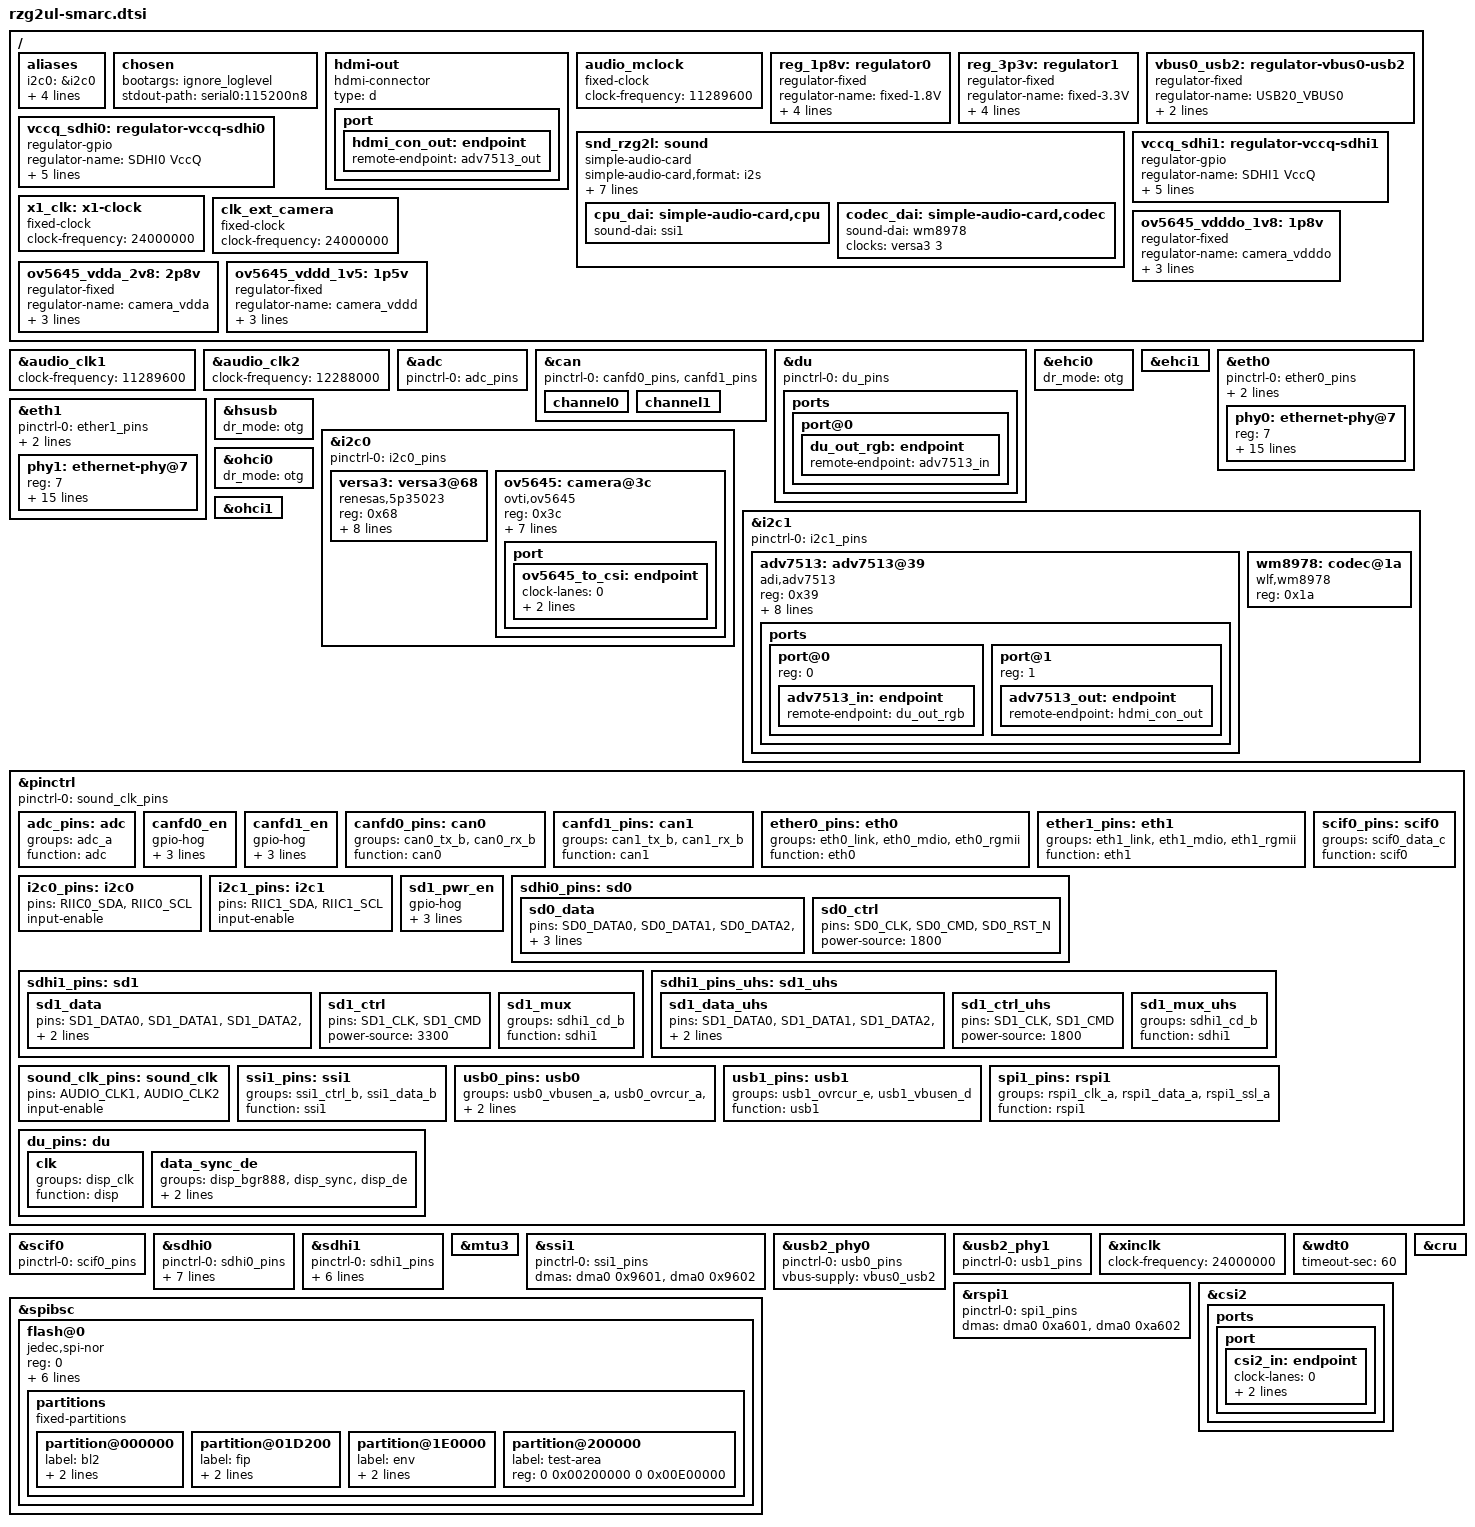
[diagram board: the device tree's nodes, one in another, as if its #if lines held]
// SPDX-License-Identifier: GPL-2.0
/*
 * Device Tree Source for the RZG2UL Evaluation Board Kit
 *
 * Copyright (C) 2021 Renesas Electronics Corp.
 */

#include <dt-bindings/pinctrl/pinctrl-rzg2l.h>
#include <dt-bindings/gpio/gpio.h>

/*
 * DIP-Switch SW1 setting
 * 1 : High; 0: Low
 * SW1-2 : SW_SD0_DEV_SEL	(1: eMMC; 0: uSD)
 * SW1-3 : SW_ET0_EN_N		(0: ETHER0; 1: CAN0,CAN1,SSI1,RSPI1)
 * Please change below MACROs corespondingly to SW1 setting
 */

#define	SW_SW0_DEV_SEL	1
#define	SW_ET0_EN_N	1

/ {
	aliases {
		i2c0 = &i2c0;
		i2c1 = &i2c1;
		serial0 = &scif0;
#if !(SW_ET0_EN_N)
		ethernet0 = &eth0;
#endif
		ethernet1 = &eth1;
	};

	chosen {
		bootargs = "ignore_loglevel";
		stdout-path = "serial0:115200n8";
	};

	hdmi-out {
		compatible = "hdmi-connector";
		type = "d";

		port {
			hdmi_con_out: endpoint {
				remote-endpoint = <&adv7513_out>;
			};
		};
	};

	audio_mclock: audio_mclock {
		compatible = "fixed-clock";
		#clock-cells = <0>;
		clock-frequency = <11289600>;
	};

	reg_1p8v: regulator0 {
		compatible = "regulator-fixed";

		regulator-name = "fixed-1.8V";
		regulator-min-microvolt = <1800000>;
		regulator-max-microvolt = <1800000>;
		regulator-boot-on;
		regulator-always-on;
	};

	reg_3p3v: regulator1 {
		compatible = "regulator-fixed";

		regulator-name = "fixed-3.3V";
		regulator-min-microvolt = <3300000>;
		regulator-max-microvolt = <3300000>;
		regulator-boot-on;
		regulator-always-on;
	};

	vbus0_usb2: regulator-vbus0-usb2 {
		compatible = "regulator-fixed";

		regulator-name = "USB20_VBUS0";
		regulator-min-microvolt = <5000000>;
		regulator-max-microvolt = <5000000>;
	};

#if (SW_ET0_EN_N)
	snd_rzg2l: sound {
		compatible = "simple-audio-card";
		simple-audio-card,format = "i2s";
		simple-audio-card,bitclock-master = <&cpu_dai>;
		simple-audio-card,frame-master = <&cpu_dai>;
		simple-audio-card,mclk-fs = <256>;

		simple-audio-card,widgets = "Microphone", "Microphone Jack";
		simple-audio-card,routing =
			    "L2", "Mic Bias",
			    "R2", "Mic Bias",
			    "Mic Bias", "Microphone Jack";

		cpu_dai: simple-audio-card,cpu {
			sound-dai = <&ssi1>;
		};

		codec_dai: simple-audio-card,codec {
			sound-dai = <&wm8978>;
			clocks = <&versa3 3>;
		};
	};
#endif

#if !(SW_SW0_DEV_SEL)
	vccq_sdhi0: regulator-vccq-sdhi0 {
		compatible = "regulator-gpio";

		regulator-name = "SDHI0 VccQ";
		regulator-min-microvolt = <1800000>;
		regulator-max-microvolt = <3300000>;

		gpios = <&pinctrl RZG2L_GPIO(6, 2) GPIO_ACTIVE_HIGH>;

		gpios-states = <1>;
		states = <3300000 1
			  1800000 0>;
	};
#endif

	vccq_sdhi1: regulator-vccq-sdhi1 {
		compatible = "regulator-gpio";

		regulator-name = "SDHI1 VccQ";
		regulator-min-microvolt = <1800000>;
		regulator-max-microvolt = <3300000>;

		gpios = <&pinctrl RZG2L_GPIO(6, 1) GPIO_ACTIVE_HIGH>;

		gpios-states = <1>;
		states = <3300000 1
			  1800000 0>;
	};

	x1_clk: x1-clock {
		compatible = "fixed-clock";
		#clock-cells = <0>;
		clock-frequency = <24000000>;
	};

	clk_ext_camera: clk_ext_camera {
		compatible = "fixed-clock";
		#clock-cells = <0>;
		clock-frequency = <24000000>;
	};

	ov5645_vdddo_1v8: 1p8v {
		compatible = "regulator-fixed";
		regulator-name = "camera_vdddo";
		regulator-min-microvolt = <1800000>;
		regulator-max-microvolt = <1800000>;
		regulator-always-on;
	};

	ov5645_vdda_2v8: 2p8v {
		compatible = "regulator-fixed";
		regulator-name = "camera_vdda";
		regulator-min-microvolt = <2800000>;
		regulator-max-microvolt = <2800000>;
		regulator-always-on;
	};

	ov5645_vddd_1v5: 1p5v {
		compatible = "regulator-fixed";
		regulator-name = "camera_vddd";
		regulator-min-microvolt = <1500000>;
		regulator-max-microvolt = <1500000>;
		regulator-always-on;
	};
};

&audio_clk1{
	clock-frequency = <11289600>;
};

&audio_clk2{
	clock-frequency = <12288000>;
};

#if (SW_SW0_DEV_SEL)
&adc {
	pinctrl-0 = <&adc_pins>;
	pinctrl-names = "default";
	status = "okay";
};
#endif

#if (SW_ET0_EN_N)
&can {
	pinctrl-0 = <&canfd0_pins &canfd1_pins>;
	pinctrl-names = "default";
	status = "okay";
	channel0 {
		status = "okay";
	};
	channel1 {
		status = "okay";
	};
};
#endif

&du {
	pinctrl-0 = <&du_pins>;
	pinctrl-names = "default";
	status = "okay";

	ports {
		port@0 {
			du_out_rgb: endpoint {
				remote-endpoint = <&adv7513_in>;
			};
		};
	};
};

&ehci0 {
	dr_mode = "otg";
	status = "okay";
};

&ehci1 {
	status = "okay";
};

#if !(SW_ET0_EN_N)
&eth0 {
	pinctrl-0 = <&ether0_pins>;
	pinctrl-names = "default";
	phy-handle = <&phy0>;
	phy-mode = "rgmii";
	status = "okay";

	phy0: ethernet-phy@7 {
		reg = <7>;
		rxc-skew-psec = <2400>;
		txc-skew-psec = <2400>;
		rxdv-skew-psec = <0>;
		txdv-skew-psec = <0>;
		rxd0-skew-psec = <0>;
		rxd1-skew-psec = <0>;
		rxd2-skew-psec = <0>;
		rxd3-skew-psec = <0>;
		txd0-skew-psec = <0>;
		txd1-skew-psec = <0>;
		txd2-skew-psec = <0>;
		txd3-skew-psec = <0>;

		interrupt-parent = <&pinctrl>;
		interrupts = <RZG2L_GPIO(5, 1) IRQ_TYPE_EDGE_FALLING>;
	};
};
#endif

&eth1 {
	pinctrl-0 = <&ether1_pins>;
	pinctrl-names = "default";
	phy-handle = <&phy1>;
	phy-mode = "rgmii";
	status = "okay";

	phy1: ethernet-phy@7 {
		reg = <7>;
		rxc-skew-psec = <2400>;
		txc-skew-psec = <2400>;
		rxdv-skew-psec = <0>;
		txdv-skew-psec = <0>;
		rxd0-skew-psec = <0>;
		rxd1-skew-psec = <0>;
		rxd2-skew-psec = <0>;
		rxd3-skew-psec = <0>;
		txd0-skew-psec = <0>;
		txd1-skew-psec = <0>;
		txd2-skew-psec = <0>;
		txd3-skew-psec = <0>;

		interrupt-parent = <&pinctrl>;
		interrupts = <RZG2L_GPIO(18, 5) IRQ_TYPE_EDGE_FALLING>;
	};
};

&hsusb {
	dr_mode = "otg";
	status = "okay";
};

&i2c0 {
	pinctrl-0 = <&i2c0_pins>;
	pinctrl-names = "default";

	status = "okay";

	versa3: versa3@68 {
		compatible = "renesas,5p35023";
		reg = <0x68>;
		#clock-cells = <1>;
		clocks = <&x1_clk>;
		clock-names = "x1";
		assigned-clocks = <&versa3 0>,
				   <&versa3 1>,
				   <&versa3 2>,
				   <&versa3 3>,
				   <&versa3 4>,
				   <&versa3 5>;
		assigned-clock-rates =	<12288000>, <25000000>,
					<12000000>, <11289600>,
					<11289600>, <24000000>;
		clock-divider-read-only = <1>, <1>, <1>, <1>, <1>;
		clock-flags = <2176>, <2176>, <2176>, <2052>, <2176>, <2048>;
	};

	ov5645: camera@3c {
		compatible = "ovti,ov5645";
		reg = <0x3c>;
		clock-names = "xclk";
		clocks = <&clk_ext_camera>;
		clock-frequency = <24000000>;
		vdddo-supply = <&ov5645_vdddo_1v8>;
		vdda-supply = <&ov5645_vdda_2v8>;
		vddd-supply = <&ov5645_vddd_1v5>;
#if (SW_ET0_EN_N)
		enable-gpios = <&pinctrl RZG2L_GPIO(4, 4) GPIO_ACTIVE_HIGH>;
#else
		/* dummy */
		enable-gpios = <&pinctrl RZG2L_GPIO(8, 1) GPIO_ACTIVE_HIGH>;
#endif
		reset-gpios = <&pinctrl RZG2L_GPIO(0, 1) GPIO_ACTIVE_LOW>;

		port {
			ov5645_to_csi: endpoint {
				clock-lanes = <0>;
				data-lanes = <1 2>;
				remote-endpoint = <&csi2_in>;
			};
		};
	};
};

&i2c1 {
	pinctrl-0 = <&i2c1_pins>;
	pinctrl-names = "default";

	status = "okay";

	adv7513: adv7513@39 {
		compatible = "adi,adv7513";
		reg = <0x39>;

		adi,input-depth = <8>;
		adi,input-colorspace = "rgb";
		adi,input-clock = "1x";

		avdd-supply = <&reg_1p8v>;
		dvdd-supply = <&reg_1p8v>;
		pvdd-supply = <&reg_1p8v>;
		dvdd-3v-supply = <&reg_3p3v>;
		bgvdd-supply = <&reg_1p8v>;

		ports {
			#address-cells = <1>;
			#size-cells = <0>;

			port@0 {
				reg = <0>;

				adv7513_in: endpoint {
					remote-endpoint = <&du_out_rgb>;
				};
			};

			port@1 {
				reg = <1>;

				adv7513_out: endpoint {
					remote-endpoint = <&hdmi_con_out>;
				};
			};
		};
	};

#if (SW_ET0_EN_N)
	wm8978: codec@1a {
		compatible = "wlf,wm8978";
		#sound-dai-cells = <0>;
		reg = <0x1a>;
	};
#endif
};

&ohci0 {
	dr_mode = "otg";
	status = "okay";
};

&ohci1 {
	status = "okay";
};

&pinctrl {
	pinctrl-0 = <&sound_clk_pins>;
	pinctrl-names = "default";

#if (SW_SW0_DEV_SEL)
	adc_pins: adc {
		groups = "adc_a";
		function = "adc";
	};
#endif

#if (SW_ET0_EN_N)
	canfd0_en {
		gpio-hog;
		gpios = <RZG2L_GPIO(2, 2) GPIO_ACTIVE_LOW>;
		output-high;
		line-name = "canfd0_en";
	};

	canfd1_en {
		gpio-hog;
		gpios = <RZG2L_GPIO(2, 3) GPIO_ACTIVE_LOW>;
		output-high;
		line-name = "canfd1_en";
	};

	canfd0_pins: can0 {
		groups = "can0_tx_b", "can0_rx_b";
		function = "can0";
	};

	canfd1_pins: can1 {
		groups = "can1_tx_b", "can1_rx_b";
		function = "can1";
	};
#endif

#if !(SW_ET0_EN_N)
	ether0_pins: eth0 {
		groups = "eth0_link", "eth0_mdio", "eth0_rgmii";
		function = "eth0";
	};
#endif
	ether1_pins: eth1 {
		groups = "eth1_link", "eth1_mdio", "eth1_rgmii";
		function = "eth1";
	};

	i2c0_pins: i2c0 {
		pins = "RIIC0_SDA", "RIIC0_SCL";
		input-enable;
	};

	i2c1_pins: i2c1 {
		pins = "RIIC1_SDA", "RIIC1_SCL";
		input-enable;
	};

	scif0_pins: scif0 {
		groups = "scif0_data_c";
		function = "scif0";
	};

	sd1_pwr_en {
		gpio-hog;
		gpios = <RZG2L_GPIO(0, 3) GPIO_ACTIVE_HIGH>;
		output-high;
		line-name = "sd1_pwr_en";
	};

#if (SW_SW0_DEV_SEL)
	/* Support pinctrl for MMC function of SDHI0*/
	sdhi0_pins: sd0 {
		sd0_data {
			pins =  "SD0_DATA0", "SD0_DATA1", "SD0_DATA2",
				"SD0_DATA3", "SD0_DATA4", "SD0_DATA5",
				"SD0_DATA6", "SD0_DATA7";
			power-source  = <1800>;
		};

		sd0_ctrl {
			pins = "SD0_CLK", "SD0_CMD", "SD0_RST_N";
			power-source = <1800>;
		};
	};
#else
	/* Support pinctrl for SD function of SDHI0 */
	sdhi0_pins: sd0 {
		sd0_data {
			pins =  "SD0_DATA0", "SD0_DATA1", "SD0_DATA2",
				"SD0_DATA3";
			power-source  = <3300>;
		};

		sd0_ctrl {
			pins = "SD0_CLK", "SD0_CMD";
			power-source = <3300>;
		};

		sd0_mux {
			groups = "sdhi0_cd_a";
			function = "sdhi0";
		};
	};

	sdhi0_pins_uhs: sd0_uhs {
		sd0_data_uhs {
			pins =	"SD0_DATA0", "SD0_DATA1", "SD0_DATA2",
				"SD0_DATA3";
			power-source  = <1800>;
		};

		sd0_ctrl_uhs {
			pins = "SD0_CLK", "SD0_CMD";
			power-source  = <1800>;
		};

		sd0_mux_uhs {
			groups = "sdhi0_cd_a";
			function = "sdhi0";
		};
	};
#endif

	sdhi1_pins: sd1 {
		sd1_data {
			pins =	"SD1_DATA0", "SD1_DATA1",
				"SD1_DATA2", "SD1_DATA3";
			power-source  = <3300>;
		};

		sd1_ctrl {
			pins = "SD1_CLK", "SD1_CMD";
			power-source  = <3300>;
		};

		sd1_mux {
			groups = "sdhi1_cd_b";
			function = "sdhi1";
		};
	};

	sdhi1_pins_uhs: sd1_uhs {
		sd1_data_uhs {
			pins =	"SD1_DATA0", "SD1_DATA1",
				"SD1_DATA2", "SD1_DATA3";
			power-source  = <1800>;
		};

		sd1_ctrl_uhs {
			pins = "SD1_CLK", "SD1_CMD";
			power-source  = <1800>;
		};

		sd1_mux_uhs {
			groups = "sdhi1_cd_b";
			function = "sdhi1";
		};
	};

	sound_clk_pins: sound_clk {
		pins = "AUDIO_CLK1", "AUDIO_CLK2";
		input-enable;
	};

#if (SW_ET0_EN_N)
	ssi1_pins: ssi1 {
		groups = "ssi1_ctrl_b", "ssi1_data_b";
		function = "ssi1";
	};
#endif

	usb0_pins: usb0 {
		groups = "usb0_vbusen_a", "usb0_ovrcur_a", "usb0_otg_id_a";
		function = "usb0";
	};

	usb1_pins: usb1 {
		groups = "usb1_ovrcur_e", "usb1_vbusen_d";
		function = "usb1";
	};

#if (SW_ET0_EN_N)
	spi1_pins: rspi1 {
		groups = "rspi1_clk_a", "rspi1_data_a", "rspi1_ssl_a";
		function = "rspi1";
	};
#endif

	du_pins: du {
		clk {
			groups = "disp_clk";
			function = "disp";
		};

		data_sync_de {
			groups = "disp_bgr888", "disp_sync", "disp_de";
			function = "disp";
			drive-strength = <2>;
		};
	};
};

&scif0 {
	pinctrl-0 = <&scif0_pins>;
	pinctrl-names = "default";
	status = "okay";
};

#if (SW_SW0_DEV_SEL)
&sdhi0 {
	pinctrl-0 = <&sdhi0_pins>;
	pinctrl-1 = <&sdhi0_pins>;
	pinctrl-names = "default", "state_uhs";

	vmmc-supply = <&reg_3p3v>;
	vqmmc-supply = <&reg_1p8v>;
	bus-width = <8>;
	mmc-hs200-1_8v;
	non-removable;
	fixed-emmc-driver-type = <1>;
	status = "okay";
};
#else
&sdhi0 {
	pinctrl-0 = <&sdhi0_pins>;
	pinctrl-1 = <&sdhi0_pins_uhs>;
	pinctrl-names = "default", "state_uhs";

	vmmc-supply = <&reg_3p3v>;
	vqmmc-supply = <&vccq_sdhi0>;

	bus-width = <4>;
	sd-uhs-sdr50;
	sd-uhs-sdr104;
	status = "okay";
};
#endif

&sdhi1 {
	pinctrl-0 = <&sdhi1_pins>;
	pinctrl-1 = <&sdhi1_pins_uhs>;
	pinctrl-names = "default", "state_uhs";

	vmmc-supply = <&reg_3p3v>;
	vqmmc-supply = <&vccq_sdhi1>;

	bus-width = <4>;
	sd-uhs-sdr50;
	sd-uhs-sdr104;
	status = "okay";
};

&mtu3 {
	status = "okay";
};

#if (SW_ET0_EN_N)
&ssi1 {
	pinctrl-0 = <&ssi1_pins>;
	pinctrl-names = "default";

	dmas = <&dma0 0x9601>,
	       <&dma0 0x9602>;
	dma-names = "tx", "rx";

	status = "okay";
};
#endif

&usb2_phy0 {
	pinctrl-0 = <&usb0_pins>;
	pinctrl-names = "default";

	vbus-supply = <&vbus0_usb2>;
	status = "okay";
};

&usb2_phy1 {
	pinctrl-0 = <&usb1_pins>;
	pinctrl-names = "default";

	status = "okay";
};

&xinclk {
	clock-frequency = <24000000>;
};

&wdt0 {
	status = "okay";
	timeout-sec = <60>;
};

#if (SW_ET0_EN_N)
&rspi1 {
	pinctrl-0 = <&spi1_pins>;
	pinctrl-names = "default";
	status = "okay";
	dmas = <&dma0 0xa601>,
	       <&dma0 0xa602>;
	dma-names = "tx", "rx";
};
#endif

&spibsc {
	status = "okay";

	flash@0 {
		compatible = "jedec,spi-nor";
		reg = <0>;
		spi-max-frequency = <30000000>;

		spi-tx-bus-width = <1>;
		spi-rx-bus-width = <1>;

		/* SPI Mode 3 */
		spi-cpol;
		spi-cpha;
		m25p,fast-read;

		partitions {
			compatible = "fixed-partitions";
			#address-cells = <2>;
			#size-cells = <2>;

			partition@000000 {
				label = "bl2";
				reg = <0 0x00000000 0 0x0001D200>;
				read-only;
			};
			partition@01D200 {
				label = "fip";
				reg = <0 0x0001D200 0 0x001C2E00>;
				read-only;
			};
			partition@1E0000 {
				label = "env";
				reg = <0 0x001E0000 0 0x00020000>;
				read-only;
			};
			partition@200000 {
				label = "test-area";
				reg = <0 0x00200000 0 0x00E00000>;
			};
		};
	};
};

&cru {
	status = "okay";
};

&csi2 {
	status = "okay";

	ports {
		port {
			csi2_in: endpoint {
				clock-lanes = <0>;
				data-lanes = <1 2>;
				remote-endpoint = <&ov5645_to_csi>;
			};
		};
	};
};
